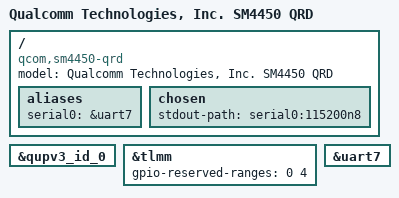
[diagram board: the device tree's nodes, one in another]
// SPDX-License-Identifier: BSD-3-Clause
/*
 * Copyright (c) 2023, Qualcomm Innovation Center, Inc. All rights reserved.
 */

/dts-v1/;

#include "sm4450.dtsi"
/ {
	model = "Qualcomm Technologies, Inc. SM4450 QRD";
	compatible = "qcom,sm4450-qrd", "qcom,sm4450";

	aliases {
		serial0 = &uart7;
	};

	chosen {
		stdout-path = "serial0:115200n8";
	};
};

&qupv3_id_0 {
	status = "okay";
};

&tlmm {
	gpio-reserved-ranges = <0 4>; /* NFC eSE SPI */
};

&uart7 {
	status = "okay";
};
